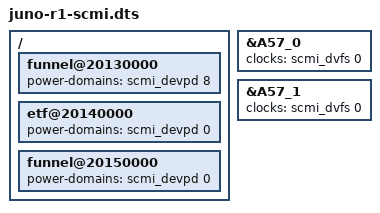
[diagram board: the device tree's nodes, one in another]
#include "juno-r1.dts"
#include "juno-scmi.dtsi"

/ {
	funnel@20130000 {
		power-domains = <&scmi_devpd 8>;
	};

	etf@20140000 {
		power-domains = <&scmi_devpd 0>;
	};

	funnel@20150000 {
		power-domains = <&scmi_devpd 0>;
	};
};

&A57_0 {
	clocks = <&scmi_dvfs 0>;
};
&A57_1 {
	clocks = <&scmi_dvfs 0>;
};
